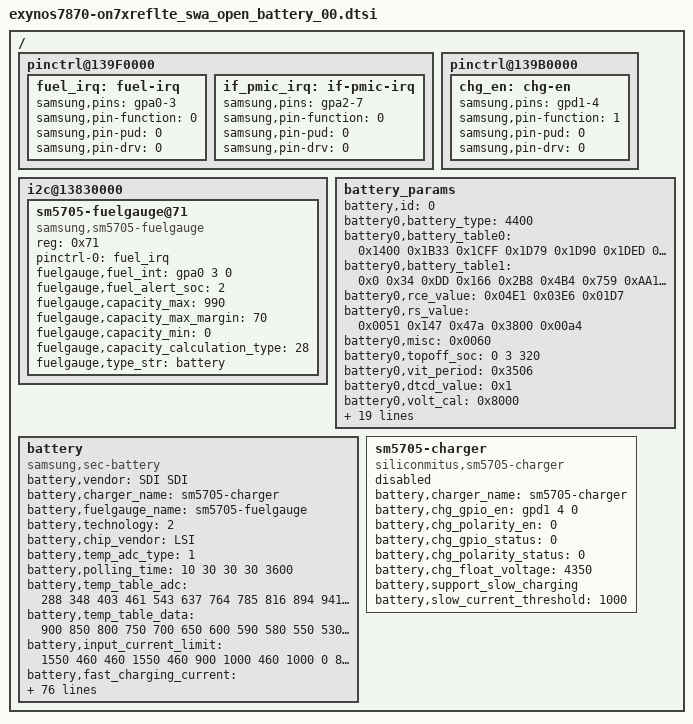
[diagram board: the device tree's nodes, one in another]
/*
 * SAMSUNG UNIVERSAL5433 board device tree source
 *
 * Copyright (c) 2013 Samsung Electronics Co., Ltd.
 *		http://www.samsung.com
 *
 * This program is free software; you can redistribute it and/or modify
 * it under the terms of the GNU General Public License version 2 as
 * published by the Free Software Foundation.
*/

/ {
	pinctrl@139F0000 {
		fuel_irq: fuel-irq {
			samsung,pins = "gpa0-3";
			samsung,pin-function = <0>;
			samsung,pin-pud = <0>;
			samsung,pin-drv = <0>;
		};
		
		if_pmic_irq: if-pmic-irq {
			samsung,pins = "gpa2-7";
			samsung,pin-function = <0>;
			samsung,pin-pud = <0>;
			samsung,pin-drv = <0>;
		};
	};
	
	pinctrl@139B0000 {
		chg_en: chg-en {
			samsung,pins = "gpd1-4";
			samsung,pin-function = <1>;
			samsung,pin-pud = <0>;
			samsung,pin-drv = <0>;
		};
	};

	i2c@13830000 {
		status = "okay";
		sm5705-fuelgauge@71 {
			compatible = "samsung,sm5705-fuelgauge";
			reg = <0x71>;
			pinctrl-names = "default";
			pinctrl-0 = <&fuel_irq>;
			fuelgauge,fuel_int = <&gpa0 3 0>;
			fuelgauge,fuel_alert_soc = <2>;
			fuelgauge,capacity_max = <990>;
			fuelgauge,capacity_max_margin = <70>;
			fuelgauge,capacity_min = <0>;
			fuelgauge,capacity_calculation_type = <28>;
			fuelgauge,type_str = "battery";
		};
	};

	battery_params {
		battery,id = <0>; /* -1 means auto, detected by F/G */
		battery0,battery_type = <4400>; /* 4200 4350 4400 */
		battery0,battery_table0 = <0x1400 0x1B33 0x1CFF 0x1D79 0x1D90 0x1DED 0x1E35 0x1E68 0x1ED5 0x1F42 0x1FAA 0x1FD3 0x206D 0x20EE 0x2225 0x2400>;
		battery0,battery_table1 = <0x0 0x34 0xDD 0x166 0x2B8 0x4B4 0x759 0xAA1 0xDEF 0xF42 0x113E 0x1290 0x13E3 0x15DF 0x196E 0x1975>;
		battery0,rce_value = <0x04E1 0x03E6 0x01D7>;
		battery0,rs_value = <0x0051 0x147 0x47a 0x3800 0x00a4>; /*rs p_mix_factor n_mix_factor max min*/
		battery0,misc = <0x0060>;
		battery0,topoff_soc = <0 3 320>; /*enable soc current*/
		battery0,vit_period = <0x3506>;
		battery0,dtcd_value = <0x1>;
		battery0,volt_cal = <0x8000>;
		battery0,curr_offset = <1 0x0000>; /*en_auto offset*/
		battery0,p_curr_cal = <0x0088>;
		battery0,n_curr_cal = <0x0088>;
		battery0,mix_value = <0x0503 0x0004>; /*mix_rate init_blank*/
		battery0,temp_std = <25>;
		battery0,temp_cal = <1 6 1 11 (-1) 1 6 1 9 1>; /* en_h, p_de, p_fa, n_de, n_fa, en_l, p_de, p_fa, n_de, n_fa, */
		battery0,ext_temp_cal = <1 3 0 3 1 1 2 3 2 3>; /* en_h, p_de, p_fa, n_de, n_fa, en_l, p_de, p_fa, n_de, n_fa, */
		battery0,temp_volcal = <1 15 1>; /* en, temp, cal */
		battery0,temp_offset = <1 11 1 1 8 (-1)>; /* en_high level offset en_low level offset */
		battery0,cycle_cfg = <7 1 3>; /*high_limit low_limit cntl*/
		battery0,curr_lcal = <0 0x8888 0x8888 0x8888>;
		battery0,tem_poff = <3380 50 3320 50>;
		battery0,v_offset_cancel = <1 0 100 10>; /* en_p, en_n, level, mohm */
		battery0,v_alarm = <3000>;
		battery0,v_max_table = <0x2225 0x21FD 0x21D5 0x21AD 0x2167>;
		battery0,q_max_table = <0x196E 0x1906 0x189D 0x1834 0x172F>;
		battery0,data_ver = <0x2>; /* this is must set value same with .version in BL */
	};

	battery {
		status = "okay";

		pinctrl-names = "default";

		compatible = "samsung,sec-battery";
		battery,vendor = "SDI SDI";
		battery,charger_name = "sm5705-charger";
		battery,fuelgauge_name = "sm5705-fuelgauge";
		battery,technology = <2>; /* POWER_SUPPLY_TECHNOLOGY_LION */

		battery,chip_vendor = "LSI";
		battery,temp_adc_type = <1>; /* SEC_BATTERY_ADC_TYPE_AP */

		battery,polling_time = <10 30 30 30 3600>;

		battery,temp_table_adc = <288 348 403 461 543 637 764 785 816 894 941 966 1025 1088 1121 1188 1369 1572
								1745 1967 2192 2427 2656 2873 2957 3001 3076 3147 3179 3238 3295 3392 3506 3571>;

		battery,temp_table_data = <900 850 800 750 700 650 600 590 580 550 530 520 500 480 470 450 400 350 
								300 250 200 150 100 50 30 20 0 (-20) (-30) (-50) (-70) (-100) (-150) (-200)>;

		battery,input_current_limit = <1550 460 460 1550 460 900 1000 460 1000 0 820 820 820 1900 1550 0 0 400 700 1300 300 1000 1550 0 1667 1667 1000 1667 80 1800 1667 1400 1000 1000 820 820>;
		battery,fast_charging_current = <1800 0 0 1800 460 1200 1000 460 1200 0 1200 1200 1200 1700 2100 0 0 400 700 1300 300 1000 1500 0 2550 2550 1000 2550 80 1800 1000 1400 0 1000 1200 1200>;
		battery,full_check_current_1st = <325 0 0 325 325 325 325 325 325 0 325 325 325 325 325 0 0 325 325 325 325 325 325 0 325 325 325 325 0 325 325 325 0 325 325 325>;
		battery,full_check_current_2nd = <175 0 0 175 175 175 175 175 175 0 175 175 175 175 175 0 0 175 175 175 175 175 175 0 175 175 175 175 0 175 175 175 0 175 175 175>;

		battery,wireless_cc_cv = <86>;
		battery,inbat_voltage = <1>;

		battery,inbat_voltage_table_adc = <2847 2829 2802 2770 2743 2715 2688 2664 2634 2603 
						2573 2544 2515 2485 2456 2431 2406 2377 2347 2317 2289 448>;
		battery,inbat_voltage_table_data = <4380 4350 4300 4250 4200 4150 4100 4050 4000 3950
						3900 3850 3800 3750 3700 3650 3600 3550 3500 3450 3400 1>;

		battery,adc_check_count = <5>;

		battery,cable_check_type = <4>; /* SEC_BATTERY_CABLE_CHECK_PSY */
		battery,cable_source_type = <1>; /* SEC_BATTERY_CABLE_SOURCE_EXTERNAL */
		battery,polling_type = <1>; /* SEC_BATTERY_MONITOR_ALARM */
		battery,monitor_initial_count = <0>;

		battery,battery_check_type = <5>; /* SEC_BATTERY_CHECK_CHARGER */
		battery,check_count = <0>;

		battery,ovp_uvlo_check_type = <3>; /* SEC_BATTERY_OVP_UVLO_CHGPOLLING */

		battery,check_adc_max = <1440>;
		battery,check_adc_min = <0>;

		battery,thermal_source = <2>; /* SEC_BATTERY_THERMAL_SOURCE_ADC */

		battery,temp_check_type = <2>; /* SEC_BATTERY_TEMP_CHECK_TEMP */
		battery,temp_check_count = <1>;
		battery,temp_highlimit_threshold_normal = <800>;
		battery,temp_highlimit_recovery_normal = <750>;
		battery,temp_high_threshold_normal = <500>;
		battery,temp_high_recovery_normal = <450>;
		battery,temp_low_threshold_normal = <0>;
		battery,temp_low_recovery_normal = <50>;
		battery,temp_highlimit_threshold_lpm = <800>;
		battery,temp_highlimit_recovery_lpm = <750>;
		battery,temp_high_threshold_lpm = <500>;
		battery,temp_high_recovery_lpm = <450>;
		battery,temp_low_threshold_lpm = <0>;
		battery,temp_low_recovery_lpm = <50>;

		battery,full_check_type = <2>; /* SEC_BATTERY_FULLCHARGED_FG_CURRENT */
		battery,full_check_type_2nd = <2>; /* SEC_BATTERY_FULLCHARGED_FG_CURRENT */
		battery,full_check_count = <2>;
		battery,chg_gpio_full_check = <0>;
		battery,chg_polarity_full_check = <1>;

		/* SEC_BATTERY_FULL_CONDITION_SOC |
		   SEC_BATTERY_FULL_CONDITION_NOTIMEFULL |
		   SEC_BATTERY_FULL_CONDITION_VCELL */
		battery,full_condition_type = <15>;
		battery,full_condition_soc = <93>;
		battery,full_condition_vcell = <4290>;

		battery,recharge_check_count = <2>;
		battery,recharge_condition_type = <4>; /* SEC_BATTERY_RECHARGE_CONDITION_VCELL */
		battery,recharge_condition_soc = <98>;
		battery,recharge_condition_vcell = <4280>;
		
		battery,expired_time = <15000>;
		battery,recharging_expired_time = <5400>;
		battery,standard_curr = <1800>;

		battery,charging_total_time = <21600>;
		battery,recharging_total_time = <5400>;
		battery,charging_reset_time = <0>;

		battery,chg_float_voltage = <4350>;

		battery,swelling_high_temp_block = <410>;
		battery,swelling_high_temp_recov = <390>;
		
		battery,swelling_low_temp_2step_mode = <1>;
		battery,swelling_low_temp_block_1st = <150>;
		battery,swelling_low_temp_recov_1st = <200>;
		battery,swelling_low_temp_block_2nd = <50>;
		battery,swelling_low_temp_recov_2nd = <100>;
		
		battery,swelling_low_temp_current = <950>;	/* 0.5C */
		battery,swelling_low_temp_topoff = <175>;	/* 0.05C */
		battery,swelling_high_temp_current = <1450>;	/* 0.7C */
		battery,swelling_high_temp_topoff = <175>;	/* 0.05C */
		
		battery,swelling_drop_float_voltage = <4150>;
		battery,swelling_offset_voltage = <20>;
		battery,swelling_high_rechg_voltage = <4000>;
		battery,swelling_low_rechg_voltage = <4000>;

		battery,siop_input_limit_current = <1550>;
		battery,siop_charging_limit_current = <1000>;

		/* cycle, chg_float_voltage, recharge_condition_vcell, full_condition_vcell, full_condition_soc */
		battery,age_data = <0 4350 4280 4250 92	/*4.35*/
				200 4330 4260 4230 91	/*4.33*/
				250 4310 4240 4210 89	/*4.31*/
				300 4290 4220 4190 87	/*4.29*/
				1000 4240 4170 4140 83	/*4.24*/
				>;

		io-channels = <&exynos_adc 1>,<&exynos_adc 3>;
		io-channel-names = "adc-temp","adc-in-bat";
		#io-channel-cells = <1>;
		io-channel-ranges;
	};

	sm5705-charger {
		status = "disable";
		compatible = "siliconmitus,sm5705-charger";

		/* Charger */
		battery,charger_name = "sm5705-charger";
		battery,chg_gpio_en = <&gpd1 4 0>;
		battery,chg_polarity_en = <0>;
		battery,chg_gpio_status = <0>;
		battery,chg_polarity_status = <0>;
		battery,chg_float_voltage = <4350>;
		battery,support_slow_charging;
		battery,slow_current_threshold = <1000>;
	};
};
